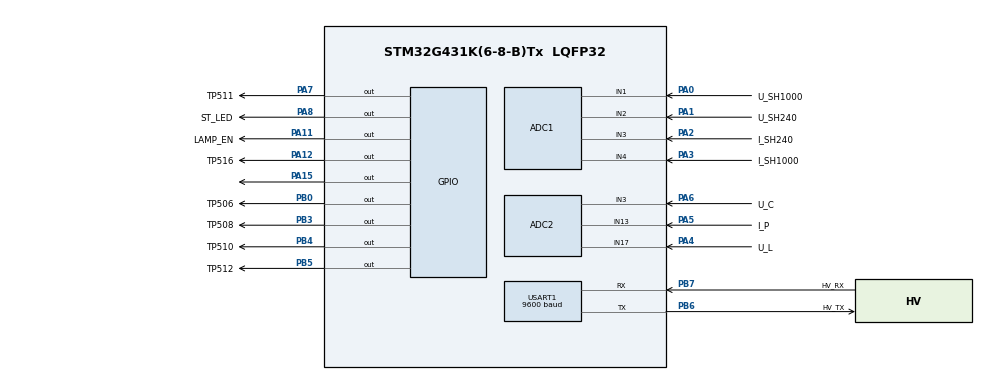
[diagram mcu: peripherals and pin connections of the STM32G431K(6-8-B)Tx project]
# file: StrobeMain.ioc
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ADC1.Channel-0\#ChannelRegularConversion=ADC_CHANNEL_1
ADC1.Channel-1\#ChannelRegularConversion=ADC_CHANNEL_2
ADC1.Channel-2\#ChannelRegularConversion=ADC_CHANNEL_3
ADC1.Channel-3\#ChannelRegularConversion=ADC_CHANNEL_4
ADC1.ClockPrescaler=ADC_CLOCK_ASYNC_DIV2
ADC1.DMAContinuousRequests=ENABLE
ADC1.EOCSelection=ADC_EOC_SEQ_CONV
ADC1.NbrOfConversion=4
ADC1.NbrOfConversionFlag=1
ADC1.OffsetNumber-0\#ChannelRegularConversion=ADC_OFFSET_NONE
ADC1.OffsetNumber-1\#ChannelRegularConversion=ADC_OFFSET_NONE
ADC1.OffsetNumber-2\#ChannelRegularConversion=ADC_OFFSET_NONE
ADC1.OffsetNumber-3\#ChannelRegularConversion=ADC_OFFSET_NONE
ADC1.Overrun=ADC_OVR_DATA_OVERWRITTEN
ADC1.Rank-0\#ChannelRegularConversion=1
ADC1.Rank-1\#ChannelRegularConversion=2
ADC1.Rank-2\#ChannelRegularConversion=3
ADC1.Rank-3\#ChannelRegularConversion=4
ADC1.SamplingTime-0\#ChannelRegularConversion=ADC_SAMPLETIME_47CYCLES_5
ADC1.SamplingTime-1\#ChannelRegularConversion=ADC_SAMPLETIME_47CYCLES_5
ADC1.SamplingTime-2\#ChannelRegularConversion=ADC_SAMPLETIME_47CYCLES_5
ADC1.SamplingTime-3\#ChannelRegularConversion=ADC_SAMPLETIME_47CYCLES_5
ADC1.master=1
ADC2.Channel-0\#ChannelRegularConversion=ADC_CHANNEL_17
ADC2.Channel-1\#ChannelRegularConversion=ADC_CHANNEL_13
ADC2.Channel-2\#ChannelRegularConversion=ADC_CHANNEL_3
ADC2.ClockPrescaler=ADC_CLOCK_ASYNC_DIV2
ADC2.DMAContinuousRequests=ENABLE
ADC2.NbrOfConversion=3
ADC2.NbrOfConversionFlag=1
ADC2.OffsetNumber-0\#ChannelRegularConversion=ADC_OFFSET_NONE
ADC2.OffsetNumber-1\#ChannelRegularConversion=ADC_OFFSET_NONE
ADC2.OffsetNumber-2\#ChannelRegularConversion=ADC_OFFSET_NONE
ADC2.Overrun=ADC_OVR_DATA_OVERWRITTEN
ADC2.Rank-0\#ChannelRegularConversion=1
ADC2.Rank-1\#ChannelRegularConversion=2
ADC2.Rank-2\#ChannelRegularConversion=3
ADC2.SamplingTime-0\#ChannelRegularConversion=ADC_SAMPLETIME_47CYCLES_5
ADC2.SamplingTime-1\#ChannelRegularConversion=ADC_SAMPLETIME_47CYCLES_5
ADC2.SamplingTime-2\#ChannelRegularConversion=ADC_SAMPLETIME_47CYCLES_5
Dma.ADC1.1.Direction=DMA_PERIPH_TO_MEMORY
Dma.ADC1.1.EventEnable=DISABLE
Dma.ADC1.1.Instance=DMA1_Channel1
Dma.ADC1.1.MemDataAlignment=DMA_MDATAALIGN_HALFWORD
Dma.ADC1.1.MemInc=DMA_MINC_ENABLE
Dma.ADC1.1.Mode=DMA_CIRCULAR
Dma.ADC1.1.PeriphDataAlignment=DMA_PDATAALIGN_HALFWORD
Dma.ADC1.1.PeriphInc=DMA_PINC_DISABLE
Dma.ADC1.1.Polarity=HAL_DMAMUX_REQ_GEN_RISING
Dma.ADC1.1.Priority=DMA_PRIORITY_LOW
Dma.ADC1.1.RequestNumber=1
Dma.ADC1.1.SignalID=NONE
Dma.ADC1.1.SyncEnable=DISABLE
Dma.ADC1.1.SyncPolarity=HAL_DMAMUX_SYNC_NO_EVENT
Dma.ADC1.1.SyncRequestNumber=1
Dma.ADC1.1.SyncSignalID=NONE
Dma.ADC2.0.Direction=DMA_PERIPH_TO_MEMORY
Dma.ADC2.0.EventEnable=DISABLE
Dma.ADC2.0.Instance=DMA1_Channel2
Dma.ADC2.0.MemDataAlignment=DMA_MDATAALIGN_HALFWORD
Dma.ADC2.0.MemInc=DMA_MINC_ENABLE
Dma.ADC2.0.Mode=DMA_CIRCULAR
Dma.ADC2.0.PeriphDataAlignment=DMA_PDATAALIGN_HALFWORD
Dma.ADC2.0.PeriphInc=DMA_PINC_DISABLE
Dma.ADC2.0.Polarity=HAL_DMAMUX_REQ_GEN_RISING
Dma.ADC2.0.Priority=DMA_PRIORITY_LOW
Dma.ADC2.0.RequestNumber=1
Dma.ADC2.0.SignalID=NONE
Dma.ADC2.0.SyncEnable=DISABLE
Dma.ADC2.0.SyncPolarity=HAL_DMAMUX_SYNC_NO_EVENT
Dma.ADC2.0.SyncRequestNumber=1
Dma.ADC2.0.SyncSignalID=NONE
Dma.Request0=ADC2
Dma.Request1=ADC1
Dma.Request2=USART1_TX
Dma.Request3=USART1_RX
Dma.USART1_RX.3.Direction=DMA_PERIPH_TO_MEMORY
Dma.USART1_RX.3.EventEnable=DISABLE
Dma.USART1_RX.3.Instance=DMA1_Channel4
Dma.USART1_RX.3.MemDataAlignment=DMA_MDATAALIGN_BYTE
Dma.USART1_RX.3.MemInc=DMA_MINC_ENABLE
Dma.USART1_RX.3.Mode=DMA_NORMAL
Dma.USART1_RX.3.PeriphDataAlignment=DMA_PDATAALIGN_BYTE
Dma.USART1_RX.3.PeriphInc=DMA_PINC_DISABLE
Dma.USART1_RX.3.Polarity=HAL_DMAMUX_REQ_GEN_RISING
Dma.USART1_RX.3.Priority=DMA_PRIORITY_LOW
Dma.USART1_RX.3.RequestNumber=1
Dma.USART1_RX.3.SignalID=NONE
Dma.USART1_RX.3.SyncEnable=DISABLE
Dma.USART1_RX.3.SyncPolarity=HAL_DMAMUX_SYNC_NO_EVENT
Dma.USART1_RX.3.SyncRequestNumber=1
Dma.USART1_RX.3.SyncSignalID=NONE
Dma.USART1_TX.2.Direction=DMA_MEMORY_TO_PERIPH
Dma.USART1_TX.2.EventEnable=DISABLE
Dma.USART1_TX.2.Instance=DMA1_Channel3
Dma.USART1_TX.2.MemDataAlignment=DMA_MDATAALIGN_BYTE
Dma.USART1_TX.2.MemInc=DMA_MINC_ENABLE
Dma.USART1_TX.2.Mode=DMA_NORMAL
Dma.USART1_TX.2.PeriphDataAlignment=DMA_PDATAALIGN_BYTE
Dma.USART1_TX.2.PeriphInc=DMA_PINC_DISABLE
Dma.USART1_TX.2.Polarity=HAL_DMAMUX_REQ_GEN_RISING
Dma.USART1_TX.2.Priority=DMA_PRIORITY_LOW
Dma.USART1_TX.2.RequestNumber=1
Dma.USART1_TX.2.SignalID=NONE
Dma.USART1_TX.2.SyncEnable=DISABLE
Dma.USART1_TX.2.SyncPolarity=HAL_DMAMUX_SYNC_NO_EVENT
Dma.USART1_TX.2.SyncRequestNumber=1
Dma.USART1_TX.2.SyncSignalID=NONE
Mcu.Family=STM32G4
Mcu.Name=STM32G431K(6-8-B)Tx
Mcu.Package=LQFP32
NVIC.DMA1_Channel1_IRQn=true\:2\:0\:true\:false\:true\:false\:true\:true
NVIC.DMA1_Channel2_IRQn=true\:2\:0\:true\:false\:true\:false\:true\:true
NVIC.DMA1_Channel3_IRQn=true\:2\:0\:true\:false\:true\:false\:true\:true
NVIC.DMA1_Channel4_IRQn=true\:2\:0\:true\:false\:true\:false\:true\:true
NVIC.PriorityGroup=NVIC_PRIORITYGROUP_4
NVIC.TIM2_IRQn=true\:0\:0\:false\:false\:true\:true\:true\:true
NVIC.TIM6_DAC_IRQn=true\:1\:0\:true\:false\:true\:true\:true\:true
PA0.GPIO_Label=U_SH1000
PA0.Mode=IN1-Single-Ended
PA0.Signal=ADC1_IN1
PA1.GPIO_Label=U_SH240
PA1.Mode=IN2-Single-Ended
PA1.Signal=ADC1_IN2
PA11.GPIO_Label=LAMP_EN
PA11.Signal=GPIO_Output
PA12.GPIO_Label=TP516
PA12.Signal=GPIO_Output
PA13.Mode=Serial_Wire
PA13.Signal=SYS_JTMS-SWDIO
PA14.Mode=Serial_Wire
PA14.Signal=SYS_JTCK-SWCLK
PA15.Signal=GPIO_Output
PA2.GPIO_Label=I_SH240
PA2.Mode=IN3-Single-Ended
PA2.Signal=ADC1_IN3
PA3.GPIO_Label=I_SH1000
PA3.Mode=IN4-Single-Ended
PA3.Signal=ADC1_IN4
PA4.GPIO_Label=U_L
PA4.Mode=IN17-Single-Ended
PA4.Signal=ADC2_IN17
PA5.GPIO_Label=I_P
PA5.Mode=IN13-Single-Ended
PA5.Signal=ADC2_IN13
PA6.GPIO_Label=U_C
PA6.Mode=IN3-Single-Ended
PA6.Signal=ADC2_IN3
PA7.GPIO_Label=TP511
PA7.Signal=GPIO_Output
PA8.GPIO_Label=ST_LED
PA8.Signal=GPIO_Output
PB0.GPIO_Label=TP506
PB0.Signal=GPIO_Output
PB3.GPIO_Label=TP508
PB3.Signal=GPIO_Output
PB4.GPIO_Label=TP510
PB4.Signal=GPIO_Output
PB5.GPIO_Label=TP512
PB5.Signal=GPIO_Output
PB6.GPIO_Label=HV_TX
PB6.Mode=Asynchronous
PB6.Signal=USART1_TX
PB7.GPIO_Label=HV_RX
PB7.Mode=Asynchronous
PB7.Signal=USART1_RX
PF0-OSC_IN.Mode=HSE-External-Oscillator
PF0-OSC_IN.Signal=RCC_OSC_IN
PF1-OSC_OUT.Mode=HSE-External-Oscillator
PF1-OSC_OUT.Signal=RCC_OSC_OUT
ProjectManager.HeapSize=0x200
ProjectManager.StackSize=0x400
ProjectManager.TargetToolchain=STM32CubeIDE
RCC.ADC12CLockSelection=RCC_ADC12CLKSOURCE_PLL
RCC.ADC12Freq_Value=15000000
RCC.AHBFreq_Value=150000000
RCC.APB1Freq_Value=150000000
RCC.APB1TimFreq_Value=150000000
RCC.APB2Freq_Value=150000000
RCC.APB2TimFreq_Value=150000000
RCC.CortexFreq_Value=150000000
RCC.EXTERNAL_CLOCK_VALUE=12288000
RCC.HCLKFreq_Value=150000000
RCC.HSE_VALUE=20000000
RCC.HSI48_VALUE=48000000
RCC.HSI_VALUE=16000000
RCC.LSE_VALUE=32768
RCC.PLLM=RCC_PLLM_DIV5
RCC.PLLN=75
RCC.PLLP=RCC_PLLP_DIV20
RCC.PLLSourceVirtual=RCC_PLLSOURCE_HSE
RCC.SYSCLKFreq_VALUE=150000000
RCC.SYSCLKSource=RCC_SYSCLKSOURCE_PLLCLK
RCC.USBFreq_Value=150000000
RCC.VCOOutputFreq_Value=300000000
TIM2.PeriodNoDither=37499625
TIM2.Prescaler=3
TIM6.PeriodNoDither=199
TIM6.Prescaler=149
USART1.BaudRate=9600
USART1.VirtualMode-Asynchronous=VM_ASYNC
VP_SYS_VS_DBSignals.Mode=DisableDeadBatterySignals
VP_TIM2_VS_ClockSourceINT.Mode=Internal
VP_TIM6_VS_ClockSourceINT.Mode=Enable_Timer
board=custom

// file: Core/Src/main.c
/* USER CODE BEGIN Header */
/**
  ******************************************************************************
  * @file           : main.c
  * @brief          : Main program body
  ******************************************************************************
  * @attention
  *
  * Copyright (c) 2025 STMicroelectronics.
  * All rights reserved.
  *
  * This software is licensed under terms that can be found in the LICENSE file
  * in the root directory of this software component.
  * If no LICENSE file comes with this software, it is provided AS-IS.
  *
  ******************************************************************************
  */
/* USER CODE END Header */
#include "main.h"

/* USER CODE BEGIN Includes */
#include "strobe.h"
/* USER CODE END Includes */

void SystemClock_Config(void);
static void MX_GPIO_Init(void);
static void MX_DMA_Init(void);
static void MX_ADC1_Init(void);
static void MX_ADC2_Init(void);
static void MX_USART1_UART_Init(void);
static void MX_TIM2_Init(void);
static void MX_TIM6_Init(void);

int main(void)
{

  /* MCU Configuration--------------------------------------------------------*/

  /* Reset of all peripherals, Initializes the Flash interface and the Systick. */
  LL_APB2_GRP1_EnableClock(LL_APB2_GRP1_PERIPH_SYSCFG);
  LL_APB1_GRP1_EnableClock(LL_APB1_GRP1_PERIPH_PWR);

  /* System interrupt init*/
  NVIC_SetPriorityGrouping(NVIC_PRIORITYGROUP_4);

  /* SysTick_IRQn interrupt configuration */
  NVIC_SetPriority(SysTick_IRQn, NVIC_EncodePriority(NVIC_GetPriorityGrouping(),15, 0));

  /** Disable the internal Pull-Up in Dead Battery pins of UCPD peripheral
  */
  LL_PWR_DisableUCPDDeadBattery();

  /* Configure the system clock */
  SystemClock_Config();

  /* Initialize all configured peripherals */
  MX_GPIO_Init();
  MX_DMA_Init();
  MX_ADC1_Init();
  MX_ADC2_Init();
  MX_USART1_UART_Init();
  MX_TIM2_Init();
  MX_TIM6_Init();

  /* Infinite loop */
  /* USER CODE BEGIN WHILE */
  while (1)
  {
	strobe_main();
    /* USER CODE END WHILE */

  }
}

void SystemClock_Config(void)
{
  LL_FLASH_SetLatency(LL_FLASH_LATENCY_4);
  while(LL_FLASH_GetLatency() != LL_FLASH_LATENCY_4)
  {
  }
  LL_PWR_SetRegulVoltageScaling(LL_PWR_REGU_VOLTAGE_SCALE1);
  LL_RCC_HSE_Enable();
   /* Wait till HSE is ready */
  while(LL_RCC_HSE_IsReady() != 1)
  {
  }

  LL_RCC_PLL_ConfigDomain_SYS(LL_RCC_PLLSOURCE_HSE, LL_RCC_PLLM_DIV_5, 75, LL_RCC_PLLR_DIV_2);
  LL_RCC_PLL_ConfigDomain_ADC(LL_RCC_PLLSOURCE_HSE, LL_RCC_PLLM_DIV_5, 75, LL_RCC_PLLP_DIV_20);
  LL_RCC_PLL_EnableDomain_SYS();
  LL_RCC_PLL_EnableDomain_ADC();
  LL_RCC_PLL_Enable();
   /* Wait till PLL is ready */
  while(LL_RCC_PLL_IsReady() != 1)
  {
  }

  LL_RCC_SetSysClkSource(LL_RCC_SYS_CLKSOURCE_PLL);
  LL_RCC_SetAHBPrescaler(LL_RCC_SYSCLK_DIV_2);
   /* Wait till System clock is ready */
  while(LL_RCC_GetSysClkSource() != LL_RCC_SYS_CLKSOURCE_STATUS_PLL)
  {
  }

  /* Insure 1us transition state at intermediate medium speed clock*/
  for (__IO uint32_t i = (170 >> 1); i !=0; i--);

  /* Set AHB prescaler*/
  LL_RCC_SetAHBPrescaler(LL_RCC_SYSCLK_DIV_1);
  LL_RCC_SetAPB1Prescaler(LL_RCC_APB1_DIV_1);
  LL_RCC_SetAPB2Prescaler(LL_RCC_APB2_DIV_1);

  LL_Init1msTick(150000000);

  LL_SetSystemCoreClock(150000000);
}

static void MX_ADC1_Init(void)
{

  LL_ADC_InitTypeDef ADC_InitStruct = {0};
  LL_ADC_REG_InitTypeDef ADC_REG_InitStruct = {0};
  LL_ADC_CommonInitTypeDef ADC_CommonInitStruct = {0};

  LL_GPIO_InitTypeDef GPIO_InitStruct = {0};

  LL_RCC_SetADCClockSource(LL_RCC_ADC12_CLKSOURCE_PLL);

  /* Peripheral clock enable */
  LL_AHB2_GRP1_EnableClock(LL_AHB2_GRP1_PERIPH_ADC12);

  LL_AHB2_GRP1_EnableClock(LL_AHB2_GRP1_PERIPH_GPIOA);
  /**ADC1 GPIO Configuration
  PA0   ------> ADC1_IN1
  PA1   ------> ADC1_IN2
  PA2   ------> ADC1_IN3
  PA3   ------> ADC1_IN4
  */
  GPIO_InitStruct.Pin = U_SH1000_Pin;
  GPIO_InitStruct.Mode = LL_GPIO_MODE_ANALOG;
  GPIO_InitStruct.Pull = LL_GPIO_PULL_NO;
  LL_GPIO_Init(U_SH1000_GPIO_Port, &GPIO_InitStruct);

  GPIO_InitStruct.Pin = U_SH240_Pin;
  GPIO_InitStruct.Mode = LL_GPIO_MODE_ANALOG;
  GPIO_InitStruct.Pull = LL_GPIO_PULL_NO;
  LL_GPIO_Init(U_SH240_GPIO_Port, &GPIO_InitStruct);

  GPIO_InitStruct.Pin = I_SH240_Pin;
  GPIO_InitStruct.Mode = LL_GPIO_MODE_ANALOG;
  GPIO_InitStruct.Pull = LL_GPIO_PULL_NO;
  LL_GPIO_Init(I_SH240_GPIO_Port, &GPIO_InitStruct);

  GPIO_InitStruct.Pin = I_SH1000_Pin;
  GPIO_InitStruct.Mode = LL_GPIO_MODE_ANALOG;
  GPIO_InitStruct.Pull = LL_GPIO_PULL_NO;
  LL_GPIO_Init(I_SH1000_GPIO_Port, &GPIO_InitStruct);

  /* ADC1 DMA Init */

  /* ADC1 Init */
  LL_DMA_SetPeriphRequest(DMA1, LL_DMA_CHANNEL_1, LL_DMAMUX_REQ_ADC1);

  LL_DMA_SetDataTransferDirection(DMA1, LL_DMA_CHANNEL_1, LL_DMA_DIRECTION_PERIPH_TO_MEMORY);

  LL_DMA_SetChannelPriorityLevel(DMA1, LL_DMA_CHANNEL_1, LL_DMA_PRIORITY_LOW);

  LL_DMA_SetMode(DMA1, LL_DMA_CHANNEL_1, LL_DMA_MODE_CIRCULAR);

  LL_DMA_SetPeriphIncMode(DMA1, LL_DMA_CHANNEL_1, LL_DMA_PERIPH_NOINCREMENT);

  LL_DMA_SetMemoryIncMode(DMA1, LL_DMA_CHANNEL_1, LL_DMA_MEMORY_INCREMENT);

  LL_DMA_SetPeriphSize(DMA1, LL_DMA_CHANNEL_1, LL_DMA_PDATAALIGN_HALFWORD);

  LL_DMA_SetMemorySize(DMA1, LL_DMA_CHANNEL_1, LL_DMA_MDATAALIGN_HALFWORD);

  /** Common config
  */
  ADC_InitStruct.Resolution = LL_ADC_RESOLUTION_12B;
  ADC_InitStruct.DataAlignment = LL_ADC_DATA_ALIGN_RIGHT;
  ADC_InitStruct.LowPowerMode = LL_ADC_LP_MODE_NONE;
  LL_ADC_Init(ADC1, &ADC_InitStruct);
  ADC_REG_InitStruct.TriggerSource = LL_ADC_REG_TRIG_SOFTWARE;
  ADC_REG_InitStruct.SequencerLength = LL_ADC_REG_SEQ_SCAN_ENABLE_4RANKS;
  ADC_REG_InitStruct.SequencerDiscont = LL_ADC_REG_SEQ_DISCONT_DISABLE;
  ADC_REG_InitStruct.ContinuousMode = LL_ADC_REG_CONV_SINGLE;
  ADC_REG_InitStruct.DMATransfer = LL_ADC_REG_DMA_TRANSFER_UNLIMITED;
  ADC_REG_InitStruct.Overrun = LL_ADC_REG_OVR_DATA_OVERWRITTEN;
  LL_ADC_REG_Init(ADC1, &ADC_REG_InitStruct);
  LL_ADC_SetGainCompensation(ADC1, 0);
  LL_ADC_SetOverSamplingScope(ADC1, LL_ADC_OVS_DISABLE);
  ADC_CommonInitStruct.CommonClock = LL_ADC_CLOCK_ASYNC_DIV2;
  ADC_CommonInitStruct.Multimode = LL_ADC_MULTI_INDEPENDENT;
  LL_ADC_CommonInit(__LL_ADC_COMMON_INSTANCE(ADC1), &ADC_CommonInitStruct);

  /* Disable ADC deep power down (enabled by default after reset state) */
  LL_ADC_DisableDeepPowerDown(ADC1);
  /* Enable ADC internal voltage regulator */
  LL_ADC_EnableInternalRegulator(ADC1);
  /* Delay for ADC internal voltage regulator stabilization. */
  /* Compute number of CPU cycles to wait for, from delay in us. */
  /* Note: Variable divided by 2 to compensate partially */
  /* CPU processing cycles (depends on compilation optimization). */
  /* Note: If system core clock frequency is below 200kHz, wait time */
  /* is only a few CPU processing cycles. */
  uint32_t wait_loop_index;
  wait_loop_index = ((LL_ADC_DELAY_INTERNAL_REGUL_STAB_US * (SystemCoreClock / (100000 * 2))) / 10);
  while(wait_loop_index != 0)
  {
    wait_loop_index--;
  }

  /** Configure Regular Channel
  */
  LL_ADC_REG_SetSequencerRanks(ADC1, LL_ADC_REG_RANK_1, LL_ADC_CHANNEL_1);
  LL_ADC_SetChannelSamplingTime(ADC1, LL_ADC_CHANNEL_1, LL_ADC_SAMPLINGTIME_47CYCLES_5);
  LL_ADC_SetChannelSingleDiff(ADC1, LL_ADC_CHANNEL_1, LL_ADC_SINGLE_ENDED);

  /** Configure Regular Channel
  */
  LL_ADC_REG_SetSequencerRanks(ADC1, LL_ADC_REG_RANK_2, LL_ADC_CHANNEL_2);
  LL_ADC_SetChannelSamplingTime(ADC1, LL_ADC_CHANNEL_2, LL_ADC_SAMPLINGTIME_47CYCLES_5);
  LL_ADC_SetChannelSingleDiff(ADC1, LL_ADC_CHANNEL_2, LL_ADC_SINGLE_ENDED);

  /** Configure Regular Channel
  */
  LL_ADC_REG_SetSequencerRanks(ADC1, LL_ADC_REG_RANK_3, LL_ADC_CHANNEL_3);
  LL_ADC_SetChannelSamplingTime(ADC1, LL_ADC_CHANNEL_3, LL_ADC_SAMPLINGTIME_47CYCLES_5);
  LL_ADC_SetChannelSingleDiff(ADC1, LL_ADC_CHANNEL_3, LL_ADC_SINGLE_ENDED);

  /** Configure Regular Channel
  */
  LL_ADC_REG_SetSequencerRanks(ADC1, LL_ADC_REG_RANK_4, LL_ADC_CHANNEL_4);
  LL_ADC_SetChannelSamplingTime(ADC1, LL_ADC_CHANNEL_4, LL_ADC_SAMPLINGTIME_47CYCLES_5);
  LL_ADC_SetChannelSingleDiff(ADC1, LL_ADC_CHANNEL_4, LL_ADC_SINGLE_ENDED);

}

static void MX_ADC2_Init(void)
{

  LL_ADC_InitTypeDef ADC_InitStruct = {0};
  LL_ADC_REG_InitTypeDef ADC_REG_InitStruct = {0};

  LL_GPIO_InitTypeDef GPIO_InitStruct = {0};

  LL_RCC_SetADCClockSource(LL_RCC_ADC12_CLKSOURCE_PLL);

  /* Peripheral clock enable */
  LL_AHB2_GRP1_EnableClock(LL_AHB2_GRP1_PERIPH_ADC12);

  LL_AHB2_GRP1_EnableClock(LL_AHB2_GRP1_PERIPH_GPIOA);
  /**ADC2 GPIO Configuration
  PA4   ------> ADC2_IN17
  PA5   ------> ADC2_IN13
  PA6   ------> ADC2_IN3
  */
  GPIO_InitStruct.Pin = U_L_Pin;
  GPIO_InitStruct.Mode = LL_GPIO_MODE_ANALOG;
  GPIO_InitStruct.Pull = LL_GPIO_PULL_NO;
  LL_GPIO_Init(U_L_GPIO_Port, &GPIO_InitStruct);

  GPIO_InitStruct.Pin = I_P_Pin;
  GPIO_InitStruct.Mode = LL_GPIO_MODE_ANALOG;
  GPIO_InitStruct.Pull = LL_GPIO_PULL_NO;
  LL_GPIO_Init(I_P_GPIO_Port, &GPIO_InitStruct);

  GPIO_InitStruct.Pin = U_C_Pin;
  GPIO_InitStruct.Mode = LL_GPIO_MODE_ANALOG;
  GPIO_InitStruct.Pull = LL_GPIO_PULL_NO;
  LL_GPIO_Init(U_C_GPIO_Port, &GPIO_InitStruct);

  /* ADC2 DMA Init */

  /* ADC2 Init */
  LL_DMA_SetPeriphRequest(DMA1, LL_DMA_CHANNEL_2, LL_DMAMUX_REQ_ADC2);

  LL_DMA_SetDataTransferDirection(DMA1, LL_DMA_CHANNEL_2, LL_DMA_DIRECTION_PERIPH_TO_MEMORY);

  LL_DMA_SetChannelPriorityLevel(DMA1, LL_DMA_CHANNEL_2, LL_DMA_PRIORITY_LOW);

  LL_DMA_SetMode(DMA1, LL_DMA_CHANNEL_2, LL_DMA_MODE_CIRCULAR);

  LL_DMA_SetPeriphIncMode(DMA1, LL_DMA_CHANNEL_2, LL_DMA_PERIPH_NOINCREMENT);

  LL_DMA_SetMemoryIncMode(DMA1, LL_DMA_CHANNEL_2, LL_DMA_MEMORY_INCREMENT);

  LL_DMA_SetPeriphSize(DMA1, LL_DMA_CHANNEL_2, LL_DMA_PDATAALIGN_HALFWORD);

  LL_DMA_SetMemorySize(DMA1, LL_DMA_CHANNEL_2, LL_DMA_MDATAALIGN_HALFWORD);

  /** Common config
  */
  ADC_InitStruct.Resolution = LL_ADC_RESOLUTION_12B;
  ADC_InitStruct.DataAlignment = LL_ADC_DATA_ALIGN_RIGHT;
  ADC_InitStruct.LowPowerMode = LL_ADC_LP_MODE_NONE;
  LL_ADC_Init(ADC2, &ADC_InitStruct);
  ADC_REG_InitStruct.TriggerSource = LL_ADC_REG_TRIG_SOFTWARE;
  ADC_REG_InitStruct.SequencerLength = LL_ADC_REG_SEQ_SCAN_ENABLE_3RANKS;
  ADC_REG_InitStruct.SequencerDiscont = LL_ADC_REG_SEQ_DISCONT_DISABLE;
  ADC_REG_InitStruct.ContinuousMode = LL_ADC_REG_CONV_SINGLE;
  ADC_REG_InitStruct.DMATransfer = LL_ADC_REG_DMA_TRANSFER_UNLIMITED;
  ADC_REG_InitStruct.Overrun = LL_ADC_REG_OVR_DATA_OVERWRITTEN;
  LL_ADC_REG_Init(ADC2, &ADC_REG_InitStruct);
  LL_ADC_SetGainCompensation(ADC2, 0);
  LL_ADC_SetOverSamplingScope(ADC2, LL_ADC_OVS_DISABLE);

  /* Disable ADC deep power down (enabled by default after reset state) */
  LL_ADC_DisableDeepPowerDown(ADC2);
  /* Enable ADC internal voltage regulator */
  LL_ADC_EnableInternalRegulator(ADC2);
  /* Delay for ADC internal voltage regulator stabilization. */
  /* Compute number of CPU cycles to wait for, from delay in us. */
  /* Note: Variable divided by 2 to compensate partially */
  /* CPU processing cycles (depends on compilation optimization). */
  /* Note: If system core clock frequency is below 200kHz, wait time */
  /* is only a few CPU processing cycles. */
  uint32_t wait_loop_index;
  wait_loop_index = ((LL_ADC_DELAY_INTERNAL_REGUL_STAB_US * (SystemCoreClock / (100000 * 2))) / 10);
  while(wait_loop_index != 0)
  {
    wait_loop_index--;
  }

  /** Configure Regular Channel
  */
  LL_ADC_REG_SetSequencerRanks(ADC2, LL_ADC_REG_RANK_1, LL_ADC_CHANNEL_17);
  LL_ADC_SetChannelSamplingTime(ADC2, LL_ADC_CHANNEL_17, LL_ADC_SAMPLINGTIME_47CYCLES_5);
  LL_ADC_SetChannelSingleDiff(ADC2, LL_ADC_CHANNEL_17, LL_ADC_SINGLE_ENDED);

  /** Configure Regular Channel
  */
  LL_ADC_REG_SetSequencerRanks(ADC2, LL_ADC_REG_RANK_2, LL_ADC_CHANNEL_13);
  LL_ADC_SetChannelSamplingTime(ADC2, LL_ADC_CHANNEL_13, LL_ADC_SAMPLINGTIME_47CYCLES_5);
  LL_ADC_SetChannelSingleDiff(ADC2, LL_ADC_CHANNEL_13, LL_ADC_SINGLE_ENDED);

  /** Configure Regular Channel
  */
  LL_ADC_REG_SetSequencerRanks(ADC2, LL_ADC_REG_RANK_3, LL_ADC_CHANNEL_3);
  LL_ADC_SetChannelSamplingTime(ADC2, LL_ADC_CHANNEL_3, LL_ADC_SAMPLINGTIME_47CYCLES_5);
  LL_ADC_SetChannelSingleDiff(ADC2, LL_ADC_CHANNEL_3, LL_ADC_SINGLE_ENDED);

}

static void MX_TIM2_Init(void)
{

  LL_TIM_InitTypeDef TIM_InitStruct = {0};

  /* Peripheral clock enable */
  LL_APB1_GRP1_EnableClock(LL_APB1_GRP1_PERIPH_TIM2);

  /* TIM2 interrupt Init */
  NVIC_SetPriority(TIM2_IRQn, NVIC_EncodePriority(NVIC_GetPriorityGrouping(),0, 0));
  NVIC_EnableIRQ(TIM2_IRQn);

  TIM_InitStruct.Prescaler = 3;
  TIM_InitStruct.CounterMode = LL_TIM_COUNTERMODE_UP;
  TIM_InitStruct.Autoreload = 37499625;
  TIM_InitStruct.ClockDivision = LL_TIM_CLOCKDIVISION_DIV1;
  LL_TIM_Init(TIM2, &TIM_InitStruct);
  LL_TIM_DisableARRPreload(TIM2);
  LL_TIM_SetClockSource(TIM2, LL_TIM_CLOCKSOURCE_INTERNAL);
  LL_TIM_SetTriggerOutput(TIM2, LL_TIM_TRGO_RESET);
  LL_TIM_DisableMasterSlaveMode(TIM2);

}

static void MX_TIM6_Init(void)
{

  LL_TIM_InitTypeDef TIM_InitStruct = {0};

  /* Peripheral clock enable */
  LL_APB1_GRP1_EnableClock(LL_APB1_GRP1_PERIPH_TIM6);

  /* TIM6 interrupt Init */
  NVIC_SetPriority(TIM6_DAC_IRQn, NVIC_EncodePriority(NVIC_GetPriorityGrouping(),1, 0));
  NVIC_EnableIRQ(TIM6_DAC_IRQn);

  TIM_InitStruct.Prescaler = 149;
  TIM_InitStruct.CounterMode = LL_TIM_COUNTERMODE_UP;
  TIM_InitStruct.Autoreload = 199;
  LL_TIM_Init(TIM6, &TIM_InitStruct);
  LL_TIM_DisableARRPreload(TIM6);
  LL_TIM_SetTriggerOutput(TIM6, LL_TIM_TRGO_RESET);
  LL_TIM_DisableMasterSlaveMode(TIM6);

}

static void MX_USART1_UART_Init(void)
{

  LL_USART_InitTypeDef USART_InitStruct = {0};

  LL_GPIO_InitTypeDef GPIO_InitStruct = {0};

  LL_RCC_SetUSARTClockSource(LL_RCC_USART1_CLKSOURCE_PCLK2);

  /* Peripheral clock enable */
  LL_APB2_GRP1_EnableClock(LL_APB2_GRP1_PERIPH_USART1);

  LL_AHB2_GRP1_EnableClock(LL_AHB2_GRP1_PERIPH_GPIOB);
  /**USART1 GPIO Configuration
  PB6   ------> USART1_TX
  PB7   ------> USART1_RX
  */
  GPIO_InitStruct.Pin = HV_TX_Pin;
  GPIO_InitStruct.Mode = LL_GPIO_MODE_ALTERNATE;
  GPIO_InitStruct.Speed = LL_GPIO_SPEED_FREQ_LOW;
  GPIO_InitStruct.OutputType = LL_GPIO_OUTPUT_PUSHPULL;
  GPIO_InitStruct.Pull = LL_GPIO_PULL_NO;
  GPIO_InitStruct.Alternate = LL_GPIO_AF_7;
  LL_GPIO_Init(HV_TX_GPIO_Port, &GPIO_InitStruct);

  GPIO_InitStruct.Pin = HV_RX_Pin;
  GPIO_InitStruct.Mode = LL_GPIO_MODE_ALTERNATE;
  GPIO_InitStruct.Speed = LL_GPIO_SPEED_FREQ_LOW;
  GPIO_InitStruct.OutputType = LL_GPIO_OUTPUT_PUSHPULL;
  GPIO_InitStruct.Pull = LL_GPIO_PULL_NO;
  GPIO_InitStruct.Alternate = LL_GPIO_AF_7;
  LL_GPIO_Init(HV_RX_GPIO_Port, &GPIO_InitStruct);

  /* USART1 DMA Init */

  /* USART1_TX Init */
  LL_DMA_SetPeriphRequest(DMA1, LL_DMA_CHANNEL_3, LL_DMAMUX_REQ_USART1_TX);

  LL_DMA_SetDataTransferDirection(DMA1, LL_DMA_CHANNEL_3, LL_DMA_DIRECTION_MEMORY_TO_PERIPH);

  LL_DMA_SetChannelPriorityLevel(DMA1, LL_DMA_CHANNEL_3, LL_DMA_PRIORITY_LOW);

  LL_DMA_SetMode(DMA1, LL_DMA_CHANNEL_3, LL_DMA_MODE_NORMAL);

  LL_DMA_SetPeriphIncMode(DMA1, LL_DMA_CHANNEL_3, LL_DMA_PERIPH_NOINCREMENT);

  LL_DMA_SetMemoryIncMode(DMA1, LL_DMA_CHANNEL_3, LL_DMA_MEMORY_INCREMENT);

  LL_DMA_SetPeriphSize(DMA1, LL_DMA_CHANNEL_3, LL_DMA_PDATAALIGN_BYTE);

  LL_DMA_SetMemorySize(DMA1, LL_DMA_CHANNEL_3, LL_DMA_MDATAALIGN_BYTE);

  /* USART1_RX Init */
  LL_DMA_SetPeriphRequest(DMA1, LL_DMA_CHANNEL_4, LL_DMAMUX_REQ_USART1_RX);

  LL_DMA_SetDataTransferDirection(DMA1, LL_DMA_CHANNEL_4, LL_DMA_DIRECTION_PERIPH_TO_MEMORY);

  LL_DMA_SetChannelPriorityLevel(DMA1, LL_DMA_CHANNEL_4, LL_DMA_PRIORITY_LOW);

  LL_DMA_SetMode(DMA1, LL_DMA_CHANNEL_4, LL_DMA_MODE_NORMAL);

  LL_DMA_SetPeriphIncMode(DMA1, LL_DMA_CHANNEL_4, LL_DMA_PERIPH_NOINCREMENT);

  LL_DMA_SetMemoryIncMode(DMA1, LL_DMA_CHANNEL_4, LL_DMA_MEMORY_INCREMENT);

  LL_DMA_SetPeriphSize(DMA1, LL_DMA_CHANNEL_4, LL_DMA_PDATAALIGN_BYTE);

  LL_DMA_SetMemorySize(DMA1, LL_DMA_CHANNEL_4, LL_DMA_MDATAALIGN_BYTE);

  USART_InitStruct.PrescalerValue = LL_USART_PRESCALER_DIV1;
  USART_InitStruct.BaudRate = 9600;
  USART_InitStruct.DataWidth = LL_USART_DATAWIDTH_8B;
  USART_InitStruct.StopBits = LL_USART_STOPBITS_1;
  USART_InitStruct.Parity = LL_USART_PARITY_NONE;
  USART_InitStruct.TransferDirection = LL_USART_DIRECTION_TX_RX;
  USART_InitStruct.HardwareFlowControl = LL_USART_HWCONTROL_NONE;
  USART_InitStruct.OverSampling = LL_USART_OVERSAMPLING_16;
  LL_USART_Init(USART1, &USART_InitStruct);
  LL_USART_SetTXFIFOThreshold(USART1, LL_USART_FIFOTHRESHOLD_1_8);
  LL_USART_SetRXFIFOThreshold(USART1, LL_USART_FIFOTHRESHOLD_1_8);
  LL_USART_DisableFIFO(USART1);
  LL_USART_ConfigAsyncMode(USART1);

  LL_USART_Enable(USART1);

  /* Polling USART1 initialisation */
  while((!(LL_USART_IsActiveFlag_TEACK(USART1))) || (!(LL_USART_IsActiveFlag_REACK(USART1))))
  {
  }

}

static void MX_DMA_Init(void)
{

  /* Init with LL driver */
  /* DMA controller clock enable */
  LL_AHB1_GRP1_EnableClock(LL_AHB1_GRP1_PERIPH_DMAMUX1);
  LL_AHB1_GRP1_EnableClock(LL_AHB1_GRP1_PERIPH_DMA1);

  /* DMA interrupt init */
  /* DMA1_Channel1_IRQn interrupt configuration */
  NVIC_SetPriority(DMA1_Channel1_IRQn, NVIC_EncodePriority(NVIC_GetPriorityGrouping(),2, 0));
  NVIC_EnableIRQ(DMA1_Channel1_IRQn);
  /* DMA1_Channel2_IRQn interrupt configuration */
  NVIC_SetPriority(DMA1_Channel2_IRQn, NVIC_EncodePriority(NVIC_GetPriorityGrouping(),2, 0));
  NVIC_EnableIRQ(DMA1_Channel2_IRQn);
  /* DMA1_Channel3_IRQn interrupt configuration */
  NVIC_SetPriority(DMA1_Channel3_IRQn, NVIC_EncodePriority(NVIC_GetPriorityGrouping(),2, 0));
  NVIC_EnableIRQ(DMA1_Channel3_IRQn);
  /* DMA1_Channel4_IRQn interrupt configuration */
  NVIC_SetPriority(DMA1_Channel4_IRQn, NVIC_EncodePriority(NVIC_GetPriorityGrouping(),2, 0));
  NVIC_EnableIRQ(DMA1_Channel4_IRQn);

}

static void MX_GPIO_Init(void)
{
  LL_GPIO_InitTypeDef GPIO_InitStruct = {0};

  /* GPIO Ports Clock Enable */
  LL_AHB2_GRP1_EnableClock(LL_AHB2_GRP1_PERIPH_GPIOF);
  LL_AHB2_GRP1_EnableClock(LL_AHB2_GRP1_PERIPH_GPIOA);
  LL_AHB2_GRP1_EnableClock(LL_AHB2_GRP1_PERIPH_GPIOB);

  /**/
  LL_GPIO_ResetOutputPin(TP511_GPIO_Port, TP511_Pin);

  /**/
  LL_GPIO_ResetOutputPin(TP506_GPIO_Port, TP506_Pin);

  /**/
  LL_GPIO_ResetOutputPin(ST_LED_GPIO_Port, ST_LED_Pin);

  /**/
  LL_GPIO_ResetOutputPin(LAMP_EN_GPIO_Port, LAMP_EN_Pin);

  /**/
  LL_GPIO_ResetOutputPin(TP516_GPIO_Port, TP516_Pin);

  /**/
  LL_GPIO_ResetOutputPin(GPIOA, LL_GPIO_PIN_15);

  /**/
  LL_GPIO_ResetOutputPin(TP508_GPIO_Port, TP508_Pin);

  /**/
  LL_GPIO_ResetOutputPin(TP510_GPIO_Port, TP510_Pin);

  /**/
  LL_GPIO_ResetOutputPin(TP512_GPIO_Port, TP512_Pin);

  /**/
  GPIO_InitStruct.Pin = TP511_Pin;
  GPIO_InitStruct.Mode = LL_GPIO_MODE_OUTPUT;
  GPIO_InitStruct.Speed = LL_GPIO_SPEED_FREQ_LOW;
  GPIO_InitStruct.OutputType = LL_GPIO_OUTPUT_PUSHPULL;
  GPIO_InitStruct.Pull = LL_GPIO_PULL_NO;
  LL_GPIO_Init(TP511_GPIO_Port, &GPIO_InitStruct);

  /**/
  GPIO_InitStruct.Pin = TP506_Pin;
  GPIO_InitStruct.Mode = LL_GPIO_MODE_OUTPUT;
  GPIO_InitStruct.Speed = LL_GPIO_SPEED_FREQ_LOW;
  GPIO_InitStruct.OutputType = LL_GPIO_OUTPUT_PUSHPULL;
  GPIO_InitStruct.Pull = LL_GPIO_PULL_NO;
  LL_GPIO_Init(TP506_GPIO_Port, &GPIO_InitStruct);

  /**/
  GPIO_InitStruct.Pin = ST_LED_Pin;
  GPIO_InitStruct.Mode = LL_GPIO_MODE_OUTPUT;
  GPIO_InitStruct.Speed = LL_GPIO_SPEED_FREQ_LOW;
  GPIO_InitStruct.OutputType = LL_GPIO_OUTPUT_PUSHPULL;
  GPIO_InitStruct.Pull = LL_GPIO_PULL_NO;
  LL_GPIO_Init(ST_LED_GPIO_Port, &GPIO_InitStruct);

  /**/
  GPIO_InitStruct.Pin = LAMP_EN_Pin;
  GPIO_InitStruct.Mode = LL_GPIO_MODE_OUTPUT;
  GPIO_InitStruct.Speed = LL_GPIO_SPEED_FREQ_LOW;
  GPIO_InitStruct.OutputType = LL_GPIO_OUTPUT_PUSHPULL;
  GPIO_InitStruct.Pull = LL_GPIO_PULL_NO;
  LL_GPIO_Init(LAMP_EN_GPIO_Port, &GPIO_InitStruct);

  /**/
  GPIO_InitStruct.Pin = TP516_Pin;
  GPIO_InitStruct.Mode = LL_GPIO_MODE_OUTPUT;
  GPIO_InitStruct.Speed = LL_GPIO_SPEED_FREQ_LOW;
  GPIO_InitStruct.OutputType = LL_GPIO_OUTPUT_PUSHPULL;
  GPIO_InitStruct.Pull = LL_GPIO_PULL_NO;
  LL_GPIO_Init(TP516_GPIO_Port, &GPIO_InitStruct);

  /**/
  GPIO_InitStruct.Pin = LL_GPIO_PIN_15;
  GPIO_InitStruct.Mode = LL_GPIO_MODE_OUTPUT;
  GPIO_InitStruct.Speed = LL_GPIO_SPEED_FREQ_LOW;
  GPIO_InitStruct.OutputType = LL_GPIO_OUTPUT_PUSHPULL;
  GPIO_InitStruct.Pull = LL_GPIO_PULL_NO;
  LL_GPIO_Init(GPIOA, &GPIO_InitStruct);

  /**/
  GPIO_InitStruct.Pin = TP508_Pin;
  GPIO_InitStruct.Mode = LL_GPIO_MODE_OUTPUT;
  GPIO_InitStruct.Speed = LL_GPIO_SPEED_FREQ_LOW;
  GPIO_InitStruct.OutputType = LL_GPIO_OUTPUT_PUSHPULL;
  GPIO_InitStruct.Pull = LL_GPIO_PULL_NO;
  LL_GPIO_Init(TP508_GPIO_Port, &GPIO_InitStruct);

  /**/
  GPIO_InitStruct.Pin = TP510_Pin;
  GPIO_InitStruct.Mode = LL_GPIO_MODE_OUTPUT;
  GPIO_InitStruct.Speed = LL_GPIO_SPEED_FREQ_LOW;
  GPIO_InitStruct.OutputType = LL_GPIO_OUTPUT_PUSHPULL;
  GPIO_InitStruct.Pull = LL_GPIO_PULL_NO;
  LL_GPIO_Init(TP510_GPIO_Port, &GPIO_InitStruct);

  /**/
  GPIO_InitStruct.Pin = TP512_Pin;
  GPIO_InitStruct.Mode = LL_GPIO_MODE_OUTPUT;
  GPIO_InitStruct.Speed = LL_GPIO_SPEED_FREQ_LOW;
  GPIO_InitStruct.OutputType = LL_GPIO_OUTPUT_PUSHPULL;
  GPIO_InitStruct.Pull = LL_GPIO_PULL_NO;
  LL_GPIO_Init(TP512_GPIO_Port, &GPIO_InitStruct);

}

void Error_Handler(void)
{
  __disable_irq();
  while (1)
  {
  }
}
